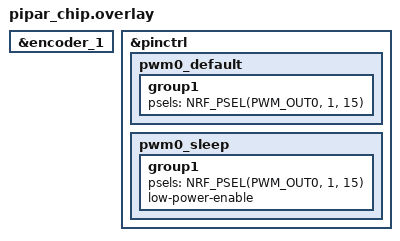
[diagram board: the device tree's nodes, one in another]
/*
 * Copyright (c) 2022 The ZMK Contributors
 *
 * SPDX-License-Identifier: MIT
 */

#include "pipar_flake.dtsi"

&encoder_1 {
    status = "okay";
};

&pinctrl {
    // Other pinctrl definitions for other hardware
    pwm0_default: pwm0_default {
        group1 {
            psels = <NRF_PSEL(PWM_OUT0, 1, 15)>;
        };
    };
    pwm0_sleep: pwm0_sleep {
        group1 {
            psels = <NRF_PSEL(PWM_OUT0, 1, 15)>;
            low-power-enable;
        };
    };
};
